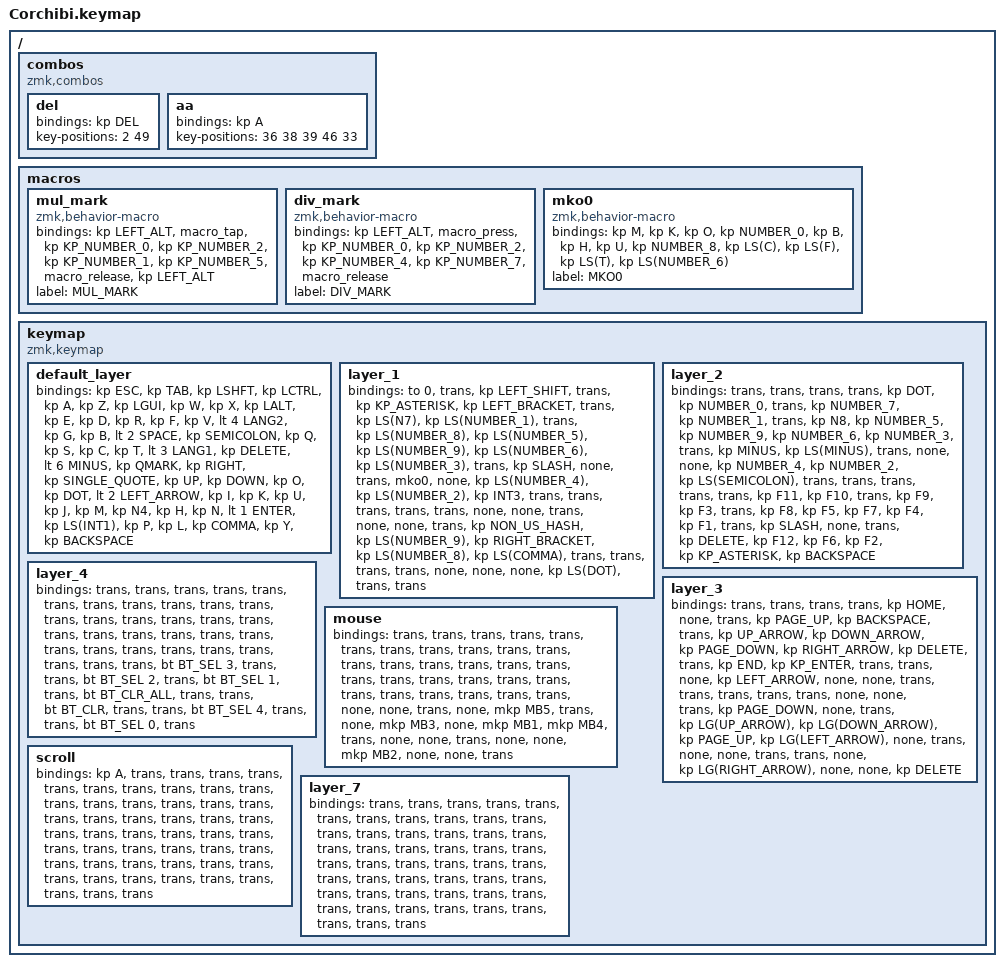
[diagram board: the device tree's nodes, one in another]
#include <dt-bindings/zmk/mouse.h>
#include <behaviors.dtsi>
#include <dt-bindings/zmk/bt.h>
#include <dt-bindings/zmk/keys.h>
#include <dt-bindings/zmk/pointing.h>

// OS設定を日本語キーボードのまま使用するための変換定義

#define JP_DQUOTE       AT                // "
#define JP_AMPERSAND    CARET             // &
#define JP_QUOTE        AMPERSAND         // '
#define JP_EQUAL        UNDER             // =
#define JP_CARET        EQUAL             // ^
#define JP_YEN          0x89              // ¥
#define JP_PLUS         COLON             // +
#define JP_TILDE        PLUS              // ~
#define JP_PIPE         LS(0x89)          // |
#define JP_AT           LEFT_BRACKET      // @
#define JP_COLON        SINGLE_QUOTE      // :
#define JP_ASTERISK     DOUBLE_QUOTES     // *
#define JP_BACKQUOTE    LEFT_BRACE        // `
#define JP_UNDERSCORE   LS(0x87)          // _
#define JP_LBRACKET     RIGHT_BRACKET     // [
#define JP_RBRACKET     BACKSLASH         // ]
#define JP_LPAREN       ASTERISK          // (
#define JP_RPAREN       LEFT_PARENTHESIS  // )
#define JP_LBRACE       RIGHT_BRACE       // {
#define JP_RBRACE       PIPE              // }
#define JP_KANA         LANGUAGE_1        // かな
#define JP_EISU         LANGUAGE_2        // 英数
#define JP_HANZEN       GRAVE             // 半角/全角

/ {
    combos {
        compatible = "zmk,combos";

        del {
            bindings = <&kp DEL>;
            key-positions = <2 49>;
        };

        aa {
            bindings = <&kp A>;
            key-positions = <36 38 39 46 33>;
        };
    };

    macros {
        mul_mark: mul_mark {
            compatible = "zmk,behavior-macro";
            #binding-cells = <0>;
            bindings =
                <&kp LEFT_ALT>,
                <&macro_tap>,
                <&kp KP_NUMBER_0 &kp KP_NUMBER_2 &kp KP_NUMBER_1 &kp KP_NUMBER_5>,
                <&macro_release>,
                <&kp LEFT_ALT>;

            label = "MUL_MARK";
        };

        div_mark: div_mark {
            compatible = "zmk,behavior-macro";
            #binding-cells = <0>;
            bindings =
                <&kp LEFT_ALT>,
                <&macro_press>,
                <&kp KP_NUMBER_0 &kp KP_NUMBER_2 &kp KP_NUMBER_4 &kp KP_NUMBER_7>,
                <&macro_release>;

            label = "DIV_MARK";
        };

        mko0: mko0 {
            compatible = "zmk,behavior-macro";
            #binding-cells = <0>;
            bindings = <&kp M &kp K &kp O &kp NUMBER_0 &kp B &kp H &kp U &kp NUMBER_8 &kp LS(C) &kp LS(F) &kp LS(T) &kp LS(NUMBER_6)>;
            label = "MKO0";
        };
    };

    keymap {
        compatible = "zmk,keymap";

        default_layer {
            bindings = <
&kp ESC  &kp TAB  &kp LSHFT  &kp LCTRL  &kp A  &kp Z  &kp LGUI  &kp W  &kp X  &kp LALT  &kp E  &kp D  &kp R  &kp F  &kp V  &lt 4 LANG2  &kp G  &kp B  &lt 2 SPACE  &kp SEMICOLON  &kp Q  &kp S  &kp C  &kp T  &lt 3 LANG1  &kp DELETE  &lt 6 MINUS  &kp QMARK  &kp RIGHT  &kp SINGLE_QUOTE  &kp UP  &kp DOWN  &kp O  &kp DOT  &lt 2 LEFT_ARROW  &kp I  &kp K  &kp U  &kp J  &kp M  &kp N4  &kp H  &kp N  &lt 1 ENTER  &kp LS(INT1)  &kp P  &kp L  &kp COMMA  &kp Y  &kp BACKSPACE
            >;
        };

        layer_1 {
            bindings = <
&to 0  &trans  &kp LEFT_SHIFT  &trans  &kp KP_ASTERISK  &kp LEFT_BRACKET  &trans  &kp LS(N7)  &kp LS(NUMBER_1)  &trans  &kp LS(NUMBER_8)  &kp LS(NUMBER_5)  &kp LS(NUMBER_9)  &kp LS(NUMBER_6)  &kp LS(NUMBER_3)  &trans  &kp SLASH  &none  &trans  &mko0  &none  &kp LS(NUMBER_4)  &kp LS(NUMBER_2)  &kp INT3  &trans  &trans  &trans  &trans  &trans  &none  &none  &trans  &none  &none  &trans  &kp NON_US_HASH  &kp LS(NUMBER_9)  &kp RIGHT_BRACKET  &kp LS(NUMBER_8)  &kp LS(COMMA)  &trans  &trans  &trans  &trans  &none  &none  &none  &kp LS(DOT)  &trans  &trans
            >;
        };

        layer_2 {
            bindings = <
&trans  &trans  &trans  &trans  &kp DOT  &kp NUMBER_0  &trans  &kp NUMBER_7  &kp NUMBER_1  &trans  &kp N8  &kp NUMBER_5  &kp NUMBER_9  &kp NUMBER_6  &kp NUMBER_3  &trans  &kp MINUS  &kp LS(MINUS)  &trans  &none  &none  &kp NUMBER_4  &kp NUMBER_2  &kp LS(SEMICOLON)  &trans  &trans  &trans  &trans  &trans  &kp F11  &kp F10  &trans  &kp F9  &kp F3  &trans  &kp F8  &kp F5  &kp F7  &kp F4  &kp F1  &trans  &kp SLASH  &none  &trans  &kp DELETE  &kp F12  &kp F6  &kp F2  &kp KP_ASTERISK  &kp BACKSPACE
            >;
        };

        layer_3 {
            bindings = <
&trans  &trans  &trans  &trans  &kp HOME  &none  &trans  &kp PAGE_UP  &kp BACKSPACE  &trans  &kp UP_ARROW  &kp DOWN_ARROW  &kp PAGE_DOWN  &kp RIGHT_ARROW  &kp DELETE  &trans  &kp END  &kp KP_ENTER  &trans  &trans  &none  &kp LEFT_ARROW  &none  &none  &trans  &trans  &trans  &trans  &trans  &none  &none  &trans  &kp PAGE_DOWN  &none  &trans  &kp LG(UP_ARROW)  &kp LG(DOWN_ARROW)  &kp PAGE_UP  &kp LG(LEFT_ARROW)  &none  &trans  &none  &none  &trans  &trans  &none  &kp LG(RIGHT_ARROW)  &none  &none  &kp DELETE
            >;
        };

        layer_4 {
            bindings = <
&trans  &trans  &trans  &trans  &trans  &trans  &trans  &trans  &trans  &trans  &trans  &trans  &trans  &trans  &trans  &trans  &trans  &trans  &trans  &trans  &trans  &trans  &trans  &trans  &trans  &trans  &trans  &trans  &trans  &trans  &trans  &trans  &bt BT_SEL 3  &trans  &trans  &bt BT_SEL 2  &trans  &bt BT_SEL 1  &trans  &bt BT_CLR_ALL  &trans  &trans  &bt BT_CLR  &trans  &trans  &bt BT_SEL 4  &trans  &trans  &bt BT_SEL 0  &trans
            >;
        };

        mouse {
            bindings = <
&trans  &trans  &trans  &trans  &trans  &trans  &trans  &trans  &trans  &trans  &trans  &trans  &trans  &trans  &trans  &trans  &trans  &trans  &trans  &trans  &trans  &trans  &trans  &trans  &trans  &trans  &trans  &trans  &trans  &none  &none  &trans  &none  &mkp MB5  &trans  &none  &mkp MB3  &none  &mkp MB1  &mkp MB4  &trans  &none  &none  &trans  &none  &none  &mkp MB2  &none  &none  &trans
            >;
        };

        scroll {
            bindings = <
&kp A  &trans  &trans  &trans  &trans  &trans  &trans  &trans  &trans  &trans  &trans  &trans  &trans  &trans  &trans  &trans  &trans  &trans  &trans  &trans  &trans  &trans  &trans  &trans  &trans  &trans  &trans  &trans  &trans  &trans  &trans  &trans  &trans  &trans  &trans  &trans  &trans  &trans  &trans  &trans  &trans  &trans  &trans  &trans  &trans  &trans  &trans  &trans  &trans  &trans
            >;
        };

        layer_7 {
            bindings = <
&trans  &trans  &trans  &trans  &trans  &trans  &trans  &trans  &trans  &trans  &trans  &trans  &trans  &trans  &trans  &trans  &trans  &trans  &trans  &trans  &trans  &trans  &trans  &trans  &trans  &trans  &trans  &trans  &trans  &trans  &trans  &trans  &trans  &trans  &trans  &trans  &trans  &trans  &trans  &trans  &trans  &trans  &trans  &trans  &trans  &trans  &trans  &trans  &trans  &trans
            >;
        };
    };
};
